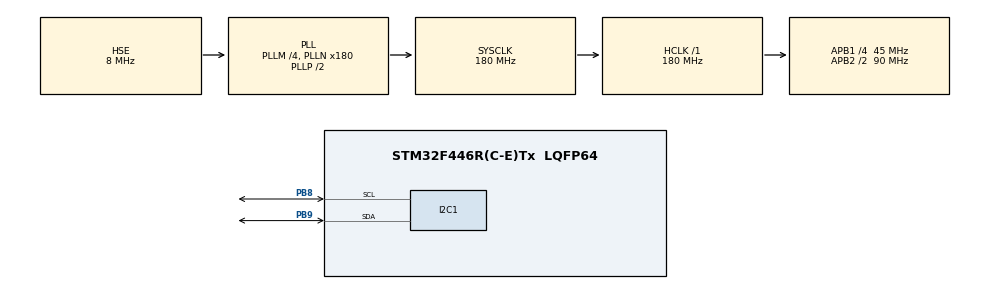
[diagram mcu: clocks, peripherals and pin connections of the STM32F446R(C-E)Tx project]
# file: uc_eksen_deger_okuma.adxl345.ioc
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Mcu.Family=STM32F4
RCC.PLLSourceVirtual=RCC_PLLSOURCE_HSE
PH0-OSC_IN.Signal=RCC_OSC_IN
RCC.CortexFreq_Value=180000000
RCC.APB1CLKDivider=RCC_HCLK_DIV4
RCC.SYSCLKSource=RCC_SYSCLKSOURCE_PLLCLK
ProjectManager.StackSize=0x400
PA13.Signal=SYS_JTMS-SWDIO
ProjectManager.TargetToolchain=STM32CubeIDE
I2C1.I2C_Mode=I2C_Fast
RCC.HCLKFreq_Value=180000000
RCC.APB2TimFreq_Value=180000000
PB9.Mode=I2C
RCC.USBFreq_Value=180000000
RCC.AHBFreq_Value=180000000
PH0-OSC_IN.Mode=HSE-External-Oscillator
RCC.HSE_VALUE=8000000
board=custom
RCC.VCOOutputFreq_Value=360000000
RCC.APB2Freq_Value=90000000
PA14.Mode=Serial_Wire
PH1-OSC_OUT.Signal=RCC_OSC_OUT
PA13.Mode=Serial_Wire
Mcu.Name=STM32F446R(C-E)Tx
PH1-OSC_OUT.Mode=HSE-External-Oscillator
RCC.SYSCLKFreq_VALUE=180000000
PB9.Signal=I2C1_SDA
Mcu.Package=LQFP64
PA14.Signal=SYS_JTCK-SWCLK
ProjectManager.HeapSize=0x200
NVIC.PriorityGroup=NVIC_PRIORITYGROUP_4
RCC.APB2CLKDivider=RCC_HCLK_DIV2
RCC.PLLM=4
PB8.Mode=I2C
RCC.PLLN=180
RCC.APB1TimFreq_Value=90000000
PB8.Signal=I2C1_SCL
RCC.APB1Freq_Value=45000000

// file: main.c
/* USER CODE BEGIN Header */
/**
  ******************************************************************************
  * @file           : main.c
  * @brief          : Main program body
  ******************************************************************************
  * @attention
  *
  * <h2><center>&copy; Copyright (c) 2022 STMicroelectronics.
  * All rights reserved.</center></h2>
  *
  * This software component is licensed by ST under BSD 3-Clause license,
  * the "License"; You may not use this file except in compliance with the
  * License. You may obtain a copy of the License at:
  *                        opensource.org/licenses/BSD-3-Clause
  *
  ******************************************************************************
  */
/* USER CODE END Header */
#include "main.h"

/* USER CODE BEGIN Includes */
#define ADXL345_ADDRESS 0xA6    //0x53<<1
/* USER CODE END Includes */

I2C_HandleTypeDef hi2c1;

/* USER CODE BEGIN PV */
uint8_t myDatas[6];
int16_t x,y,z;
float xg, yg, zg;
/* USER CODE END PV */

void SystemClock_Config(void);
static void MX_GPIO_Init(void);
static void MX_I2C1_Init(void);
/* USER CODE BEGIN PFP */
void ADXL345_ScanAdress();
void ADXL345_Init();
void ADXL345_Write(uint8_t rRegister, uint8_t value);
void ADXL345_Read(uint8_t rRegister, uint8_t numberOfBytes);
void ADXL345_AccelRead();
/* USER CODE END PFP */

int main(void)
{

  /* MCU Configuration--------------------------------------------------------*/

  /* Reset of all peripherals, Initializes the Flash interface and the Systick. */
  HAL_Init();

  /* Configure the system clock */
  SystemClock_Config();

  /* Initialize all configured peripherals */
  MX_GPIO_Init();
  MX_I2C1_Init();
  /* USER CODE BEGIN 2 */
  ADXL345_ScanAdress();
  ADXL345_Init();
  /* USER CODE END 2 */

  /* Infinite loop */
  while (1)
  {

    /* USER CODE BEGIN 3 */
	  ADXL345_AccelRead();
	  HAL_Delay(1000);
  }
  /* USER CODE END 3 */
}

void SystemClock_Config(void)
{
  RCC_OscInitTypeDef RCC_OscInitStruct = {0};
  RCC_ClkInitTypeDef RCC_ClkInitStruct = {0};

  /** Configure the main internal regulator output voltage
  */
  __HAL_RCC_PWR_CLK_ENABLE();
  __HAL_PWR_VOLTAGESCALING_CONFIG(PWR_REGULATOR_VOLTAGE_SCALE1);
  /** Initializes the RCC Oscillators according to the specified parameters
  * in the RCC_OscInitTypeDef structure.
  */
  RCC_OscInitStruct.OscillatorType = RCC_OSCILLATORTYPE_HSE;
  RCC_OscInitStruct.HSEState = RCC_HSE_ON;
  RCC_OscInitStruct.PLL.PLLState = RCC_PLL_ON;
  RCC_OscInitStruct.PLL.PLLSource = RCC_PLLSOURCE_HSE;
  RCC_OscInitStruct.PLL.PLLM = 4;
  RCC_OscInitStruct.PLL.PLLN = 180;
  RCC_OscInitStruct.PLL.PLLP = RCC_PLLP_DIV2;
  RCC_OscInitStruct.PLL.PLLQ = 2;
  RCC_OscInitStruct.PLL.PLLR = 2;
  if (HAL_RCC_OscConfig(&RCC_OscInitStruct) != HAL_OK)
  {
    Error_Handler();
  }
  /** Activate the Over-Drive mode
  */
  if (HAL_PWREx_EnableOverDrive() != HAL_OK)
  {
    Error_Handler();
  }
  /** Initializes the CPU, AHB and APB buses clocks
  */
  RCC_ClkInitStruct.ClockType = RCC_CLOCKTYPE_HCLK|RCC_CLOCKTYPE_SYSCLK
                              |RCC_CLOCKTYPE_PCLK1|RCC_CLOCKTYPE_PCLK2;
  RCC_ClkInitStruct.SYSCLKSource = RCC_SYSCLKSOURCE_PLLCLK;
  RCC_ClkInitStruct.AHBCLKDivider = RCC_SYSCLK_DIV1;
  RCC_ClkInitStruct.APB1CLKDivider = RCC_HCLK_DIV4;
  RCC_ClkInitStruct.APB2CLKDivider = RCC_HCLK_DIV2;

  if (HAL_RCC_ClockConfig(&RCC_ClkInitStruct, FLASH_LATENCY_5) != HAL_OK)
  {
    Error_Handler();
  }
}

static void MX_I2C1_Init(void)
{

  hi2c1.Instance = I2C1;
  hi2c1.Init.ClockSpeed = 400000;
  hi2c1.Init.DutyCycle = I2C_DUTYCYCLE_2;
  hi2c1.Init.OwnAddress1 = 0;
  hi2c1.Init.AddressingMode = I2C_ADDRESSINGMODE_7BIT;
  hi2c1.Init.DualAddressMode = I2C_DUALADDRESS_DISABLE;
  hi2c1.Init.OwnAddress2 = 0;
  hi2c1.Init.GeneralCallMode = I2C_GENERALCALL_DISABLE;
  hi2c1.Init.NoStretchMode = I2C_NOSTRETCH_DISABLE;
  if (HAL_I2C_Init(&hi2c1) != HAL_OK)
  {
    Error_Handler();
  }

}

static void MX_GPIO_Init(void)
{

  /* GPIO Ports Clock Enable */
  __HAL_RCC_GPIOH_CLK_ENABLE();
  __HAL_RCC_GPIOA_CLK_ENABLE();
  __HAL_RCC_GPIOB_CLK_ENABLE();

}

/* USER CODE BEGIN 4 */
void ADXL345_ScanAdress()
{
	for(int i=0; i<=255; i++)
	{
		if(HAL_I2C_IsDeviceReady(&hi2c1, i, 1, 10) == HAL_OK)
			break;
	}
}

void ADXL345_Init()
{
	ADXL345_Read(0x00, 1);
	ADXL345_Write(0x2D, 0);
	ADXL345_Write(0x2D, 0x08);      //Measure Bit SET
	ADXL345_Write(0x31, 0x01);      //Range Bit +-4g
}

void ADXL345_Write(uint8_t rRegister, uint8_t value)
{
	uint8_t data[2] = {0};
	data[0] = rRegister;
	data[1] = value;

	HAL_I2C_Master_Transmit(&hi2c1, ADXL345_ADDRESS, data, 2, 100);
}

void ADXL345_Read(uint8_t rRegister, uint8_t numberOfBytes)
{
	HAL_I2C_Mem_Read(&hi2c1, ADXL345_ADDRESS, rRegister, 1, myDatas, numberOfBytes, 100);
}

void ADXL345_AccelRead()
{
	 ADXL345_Read(0x32, 6);

	 x= (myDatas[1] << 8) | myDatas[0];
	 y= (myDatas[3] << 8) | myDatas[2];
	 z= (myDatas[5] << 8) | myDatas[4];

	 xg = x * .0078;
	 yg = y * .0078;
	 zg = z * .0078;
}
/* USER CODE END 4 */

void Error_Handler(void)
{
  __disable_irq();
  while (1)
  {
  }
}

/************************ (C) COPYRIGHT STMicroelectronics *****END OF FILE****/
